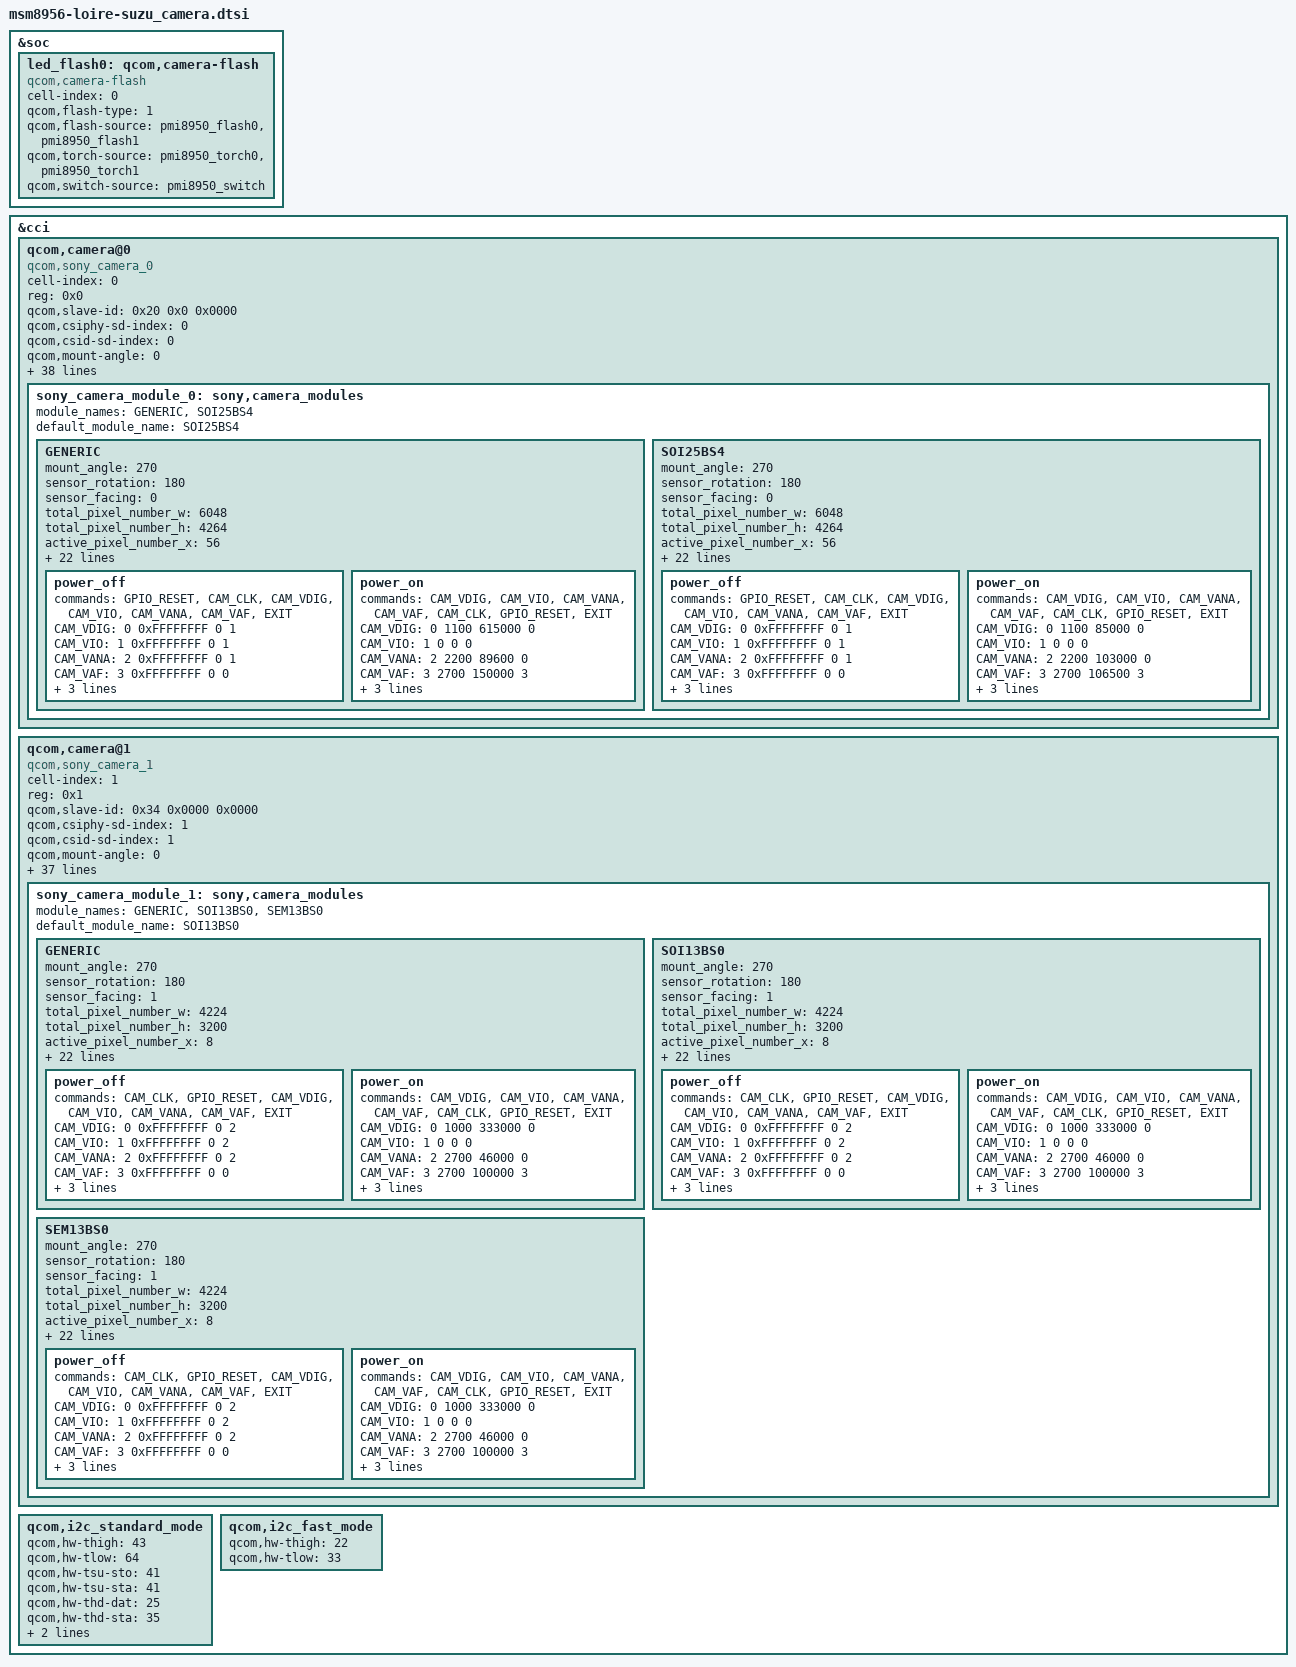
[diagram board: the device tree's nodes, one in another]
/*
 * Copyright (c) 2015-2016, The Linux Foundation. All rights reserved.
 *
 * This program is free software; you can redistribute it and/or modify
 * it under the terms of the GNU General Public License version 2 and
 * only version 2 as published by the Free Software Foundation.
 *
 * This program is distributed in the hope that it will be useful,
 * but WITHOUT ANY WARRANTY; without even the implied warranty of
 * MERCHANTABILITY or FITNESS FOR A PARTICULAR PURPOSE.  See the
 * GNU General Public License for more details.
 */

&soc {
	led_flash0: qcom,camera-flash {
		cell-index = <0>;
		compatible = "qcom,camera-flash";
		qcom,flash-type = <1>;
		qcom,flash-source = <&pmi8950_flash0 &pmi8950_flash1>;
		qcom,torch-source = <&pmi8950_torch0 &pmi8950_torch1>;
		qcom,switch-source = <&pmi8950_switch>;
	};
};

&cci {
	qcom,camera@0 {
		cell-index = <0>;
		compatible = "qcom,sony_camera_0";
		reg = <0x0>;
		status = "ok";
		qcom,slave-id = <0x20 0x0 0x0000>;
		qcom,csiphy-sd-index = <0>;
		qcom,csid-sd-index = <0>;
		qcom,mount-angle = <0>;
		qcom,sensor-name = "sony_camera_0";
		qcom,led-flash-src = <&led_flash0>;
		cam_vdig-supply = <&pm8950_l3>;
		cam_vio-supply = <&pm8950_l5>;
		cam_vana-supply = <&pm8950_l9>;
		cam_vaf-supply = <&pm8950_l17>;
		qcom,cam-vreg-name = "cam_vdig", "cam_vio", "cam_vana", "cam_vaf";
		qcom,cam-vreg-type = <0 1 0 0>;
		qcom,cam-vreg-min-voltage = <1100000 0 2200000 2700000>;
		qcom,cam-vreg-max-voltage = <1100000 0 2200000 2700000>;
		qcom,cam-vreg-op-mode = <615000 0 89600 150000>;
		qcom,gpio-no-mux = <0>;
		pinctrl-names = "cam_default", "cam_suspend";
		pinctrl-0 = <&cam_sensor_mclk0_default &cam_sensor_rear_default>;
		pinctrl-1 = <&cam_sensor_mclk0_sleep &cam_sensor_rear_sleep>;
		gpios = <&msm_gpio 26 0>, <&msm_gpio 35 0>, <&msm_gpio 127 0>;
		qcom,gpio-reset = <1>;
		qcom,gpio-vio = <2>;
		qcom,gpio-req-tbl-num = <0 1 2>;
		qcom,gpio-req-tbl-flags = <1 0 0>;
		qcom,gpio-req-tbl-label = "CAMIF_MCLK0", "CAM_RESET0", "CAM_VIO";
		qcom,csi-lane-assign = <0x4320>;
		qcom,csi-lane-mask = <0x1F>;
		qcom,sensor-position = <0>;
		qcom,sensor-mode = <1>;
		qcom,cci-master = <0>;
		clocks = <&clock_gcc clk_mclk0_clk_src>, <&clock_gcc clk_gcc_camss_mclk0_clk>;
		clock-names = "cam_src_clk", "cam_clk";
		sony,i2c_addr = <0x20>;
		sony,eeprom_addr = <0xA0>;
		sony,eeprom_type = <0>;
		sony,eeprom_max_len = <2048>;
		sony,subdev_code = <0x3007>;
		sony_camera_module_0: sony,camera_modules {
		    status = "disabled";
		};
	};

	qcom,camera@1 {
		cell-index = <1>;
		compatible = "qcom,sony_camera_1";
		reg = <0x1>;
		status = "ok";
		qcom,slave-id = <0x34 0x0000 0x0000>;
		qcom,csiphy-sd-index = <1>;
		qcom,csid-sd-index = <1>;
		qcom,mount-angle = <0>;
		qcom,sensor-name = "sony_camera_1";
		cam_vdig-supply = <&pm8950_l1>;
		cam_vana-supply = <&pm8950_l10>;
		cam_vio-supply = <&pm8950_l5>;
		cam_vaf-supply = <&pm8950_l17>;
		qcom,cam-vreg-name = "cam_vdig", "cam_vana", "cam_vio", "cam_vaf";
		qcom,cam-vreg-type = <0 0 1 0>;
		qcom,cam-vreg-min-voltage = <1000000 2700000 0 2700000>;
		qcom,cam-vreg-max-voltage = <1000000 2700000 0 2700000>;
		qcom,cam-vreg-op-mode = <333000 46000 0 100000>;
		qcom,gpio-no-mux = <0>;
		pinctrl-names = "cam_default", "cam_suspend";
		pinctrl-0 = <&cam_sensor_mclk2_default &cam_sensor_front1_default>;
		pinctrl-1 = <&cam_sensor_mclk2_sleep &cam_sensor_front1_sleep>;
		gpios = <&msm_gpio 28 0>, <&msm_gpio 38 0>, <&msm_gpio 127 0>;
		qcom,gpio-reset = <1>;
		qcom,gpio-vio = <2>;
		qcom,gpio-req-tbl-num = <0 1 2>;
		qcom,gpio-req-tbl-flags = <1 0 0>;
		qcom,gpio-req-tbl-label = "CAMIF_MCLK2", "CAM_RESET2", "CAM_VIO";
		qcom,csi-lane-assign = <0x4320>;
		qcom,csi-lane-mask = <0x1F>;
		qcom,sensor-position = <1>;
		qcom,sensor-mode = <1>;
		qcom,cci-master = <1>;
		clocks = <&clock_gcc clk_mclk2_clk_src>, <&clock_gcc clk_gcc_camss_mclk2_clk>;
		clock-names = "cam_src_clk", "cam_clk";
		sony,i2c_addr = <0x34>;
		sony,eeprom_addr = <0xA0>;
		sony,eeprom_type = <0>;
		sony,eeprom_max_len = <2048>;
		sony,subdev_code = <0x3007>;
		sony_camera_module_1: sony,camera_modules {
		    status = "disabled";
		};
	};

	qcom,i2c_standard_mode {
		qcom,hw-thigh = <43>;
		qcom,hw-tlow = <64>;
		qcom,hw-tsu-sto = <41>;
		qcom,hw-tsu-sta = <41>;
		qcom,hw-thd-dat = <25>;
		qcom,hw-thd-sta = <35>;
		qcom,hw-tbuf = <64>;
		qcom,cci-clk-src = <37500000>;
	};

	qcom,i2c_fast_mode {
		qcom,hw-thigh = <22>;
		qcom,hw-tlow = <33>;
	};
};

&sony_camera_module_0 {
	module_names = "GENERIC", "SOI25BS4";
	default_module_name = "SOI25BS4";
	status = "ok";

	GENERIC {
		mount_angle = <270>;
		sensor_rotation = <180>;
		sensor_facing = <0>;
		total_pixel_number_w = <6048>;
		total_pixel_number_h = <4264>;
		active_pixel_number_x = <56>;
		active_pixel_number_y = <88>;
		active_pixel_number_w = <5984>;
		active_pixel_number_h = <4160>;
		min_focus_distance = <120>;
		hyper_focal_distance = <3679>;
		diagonal_len = "8.17";
		unit_cell_size_w = "1.12";
		unit_cell_size_h = "1.12";
		min_f_number = "2.00";
		max_f_number = "2.00";
		has_3a = <0>;
		has_focus_actuator = <1>;
		need_standby_af = <0>;
		i2c_freq_mode = <3>;
		has_pdaf = <1>;
		has_rs = <1>;
		pdaf_free_area_num = <8>;
		pdaf_fixed_area_size_w = <16>;
		pdaf_fixed_area_size_h = <12>;
		pll_num = <26>;
		pll = <145 109 112 112 122 109 182 75 112 136 145 182 182 145 142 145 104 182 145 145 182 182 182 182 104 112>;
		power_off {
			commands =
				"GPIO_RESET",
				"CAM_CLK",
				"CAM_VDIG",
				"CAM_VIO",
				"CAM_VANA",
				"CAM_VAF",
				"EXIT";
			CAM_VDIG = <0 0xFFFFFFFF 0 1>;
			CAM_VIO = <1 0xFFFFFFFF 0 1>;
			CAM_VANA = <2 0xFFFFFFFF 0 1>;
			CAM_VAF = <3 0xFFFFFFFF 0 0>;
			GPIO_RESET = <8 0x0 0 5>;
			CAM_CLK = <9 0xFFFFFFFF 0 0>;
			EXIT = <11 0x0 0 0>;
		};
		power_on {
			commands =
				"CAM_VDIG",
				"CAM_VIO",
				"CAM_VANA",
				"CAM_VAF",
				"CAM_CLK",
				"GPIO_RESET",
				"EXIT";
			CAM_VDIG = <0 1100 615000 0>;
			CAM_VIO = <1 0 0 0>;
			CAM_VANA = <2 2200 89600 0>;
			CAM_VAF = <3 2700 150000 3>;
			CAM_CLK = <9 0 0 1>;
			GPIO_RESET = <8 1 0 9>;
			EXIT = <11 0x0 0 0>;
		};
	};
	SOI25BS4 {
		mount_angle = <270>;
		sensor_rotation = <180>;
		sensor_facing = <0>;
		total_pixel_number_w = <6048>;
		total_pixel_number_h = <4264>;
		active_pixel_number_x = <56>;
		active_pixel_number_y = <88>;
		active_pixel_number_w = <5984>;
		active_pixel_number_h = <4160>;
		min_focus_distance = <120>;
		hyper_focal_distance = <3679>;
		diagonal_len = "8.17";
		unit_cell_size_w = "1.12";
		unit_cell_size_h = "1.12";
		min_f_number = "2.00";
		max_f_number = "2.00";
		has_3a = <0>;
		has_focus_actuator = <1>;
		need_standby_af = <0>;
		i2c_freq_mode = <3>;
		has_pdaf = <1>;
		has_rs = <1>;
		pdaf_free_area_num = <8>;
		pdaf_fixed_area_size_w = <16>;
		pdaf_fixed_area_size_h = <12>;
		pll_num = <26>;
		pll = <145 109 112 112 122 109 182 75 112 136 145 182 182 145 142 145 104 182 145 145 182 182 182 182 104 112>;
		power_off {
			commands =
				"GPIO_RESET",
				"CAM_CLK",
				"CAM_VDIG",
				"CAM_VIO",
				"CAM_VANA",
				"CAM_VAF",
				"EXIT";
			CAM_VDIG = <0 0xFFFFFFFF 0 1>;
			CAM_VIO = <1 0xFFFFFFFF 0 1>;
			CAM_VANA = <2 0xFFFFFFFF 0 1>;
			CAM_VAF = <3 0xFFFFFFFF 0 0>;
			GPIO_RESET = <8 0x0 0 5>;
			CAM_CLK = <9 0xFFFFFFFF 0 0>;
			EXIT = <11 0x0 0 0>;
		};
		power_on {
			commands =
				"CAM_VDIG",
				"CAM_VIO",
				"CAM_VANA",
				"CAM_VAF",
				"CAM_CLK",
				"GPIO_RESET",
				"EXIT";
			CAM_VDIG = <0 1100 85000 0>;
			CAM_VIO = <1 0 0 0>;
			CAM_VANA = <2 2200 103000 0>;
			CAM_VAF = <3 2700 106500 3>;
			CAM_CLK = <9 0 0 1>;
			GPIO_RESET = <8 1 0 9>;
			EXIT = <11 0x0 0 0>;
		};
	};
};

&sony_camera_module_1 {
	module_names = "GENERIC", "SOI13BS0", "SEM13BS0";
	default_module_name = "SOI13BS0";
	status = "ok";

	GENERIC {
		mount_angle = <270>;
		sensor_rotation = <180>;
		sensor_facing = <1>;
		total_pixel_number_w = <4224>;
		total_pixel_number_h = <3200>;
		active_pixel_number_x = <8>;
		active_pixel_number_y = <72>;
		active_pixel_number_w = <4208>;
		active_pixel_number_h = <3120>;
		min_focus_distance = <100>;
		hyper_focal_distance = <2000>;
		diagonal_len = "5.867";
		unit_cell_size_w = "1.12";
		unit_cell_size_h = "1.12";
		min_f_number = "2.00";
		max_f_number = "2.00";
		has_3a = <0>;
		has_focus_actuator = <1>;
		need_standby_af = <1>;
		i2c_freq_mode = <0>;
		has_pdaf = <0>;
		has_rs = <1>;
		pdaf_free_area_num = <0>;
		pdaf_fixed_area_size_w = <0>;
		pdaf_fixed_area_size_h = <0>;
		pll_num = <26>;
		pll = <1134 1134 1134 1134 1134 1134 1134 1134 1134 1134 1134 1134 1134 1134 1134 1134 1134 1134 1134 1134 1134 1134 1134 1134 1134 1134>;
		power_off {
			commands =
				"CAM_CLK",
				"GPIO_RESET",
				"CAM_VDIG",
				"CAM_VIO",
				"CAM_VANA",
				"CAM_VAF",
				"EXIT";
			CAM_VDIG = <0 0xFFFFFFFF 0 2>;
			CAM_VIO = <1 0xFFFFFFFF 0 2>;
			CAM_VANA = <2 0xFFFFFFFF 0 2>;
			CAM_VAF = <3 0xFFFFFFFF 0 0>;
			GPIO_RESET = <8 0x0 0 5>;
			CAM_CLK = <9 0xFFFFFFFF 0 0>;
			EXIT = <11 0x0 0 0>;
		};
		power_on {
			commands =
				"CAM_VDIG",
				"CAM_VIO",
				"CAM_VANA",
				"CAM_VAF",
				"CAM_CLK",
				"GPIO_RESET",
				"EXIT";
			CAM_VDIG = <0 1000 333000 0>;
			CAM_VIO = <1 0 0 0>;
			CAM_VANA = <2 2700 46000 0>;
			CAM_VAF = <3 2700 100000 3>;
			CAM_CLK = <9 0 0 1>;
			GPIO_RESET = <8 1 0 1>;
			EXIT = <11 0x0 0 0>;
		};
	};
	SOI13BS0 {
		mount_angle = <270>;
		sensor_rotation = <180>;
		sensor_facing = <1>;
		total_pixel_number_w = <4224>;
		total_pixel_number_h = <3200>;
		active_pixel_number_x = <8>;
		active_pixel_number_y = <72>;
		active_pixel_number_w = <4208>;
		active_pixel_number_h = <3120>;
		min_focus_distance = <100>;
		hyper_focal_distance = <2000>;
		diagonal_len = "5.867";
		unit_cell_size_w = "1.12";
		unit_cell_size_h = "1.12";
		min_f_number = "2.00";
		max_f_number = "2.00";
		has_3a = <0>;
		has_focus_actuator = <1>;
		need_standby_af = <1>;
		i2c_freq_mode = <0>;
		has_pdaf = <0>;
		has_rs = <1>;
		pdaf_free_area_num = <0>;
		pdaf_fixed_area_size_w = <0>;
		pdaf_fixed_area_size_h = <0>;
		pll_num = <26>;
		pll = <1134 1134 1134 1134 1134 1134 1134 1134 1134 1134 1134 1134 1134 1134 1134 1134 1134 1134 1134 1134 1134 1134 1134 1134 1134 1134>;
		power_off {
			commands =
				"CAM_CLK",
				"GPIO_RESET",
				"CAM_VDIG",
				"CAM_VIO",
				"CAM_VANA",
				"CAM_VAF",
				"EXIT";
			CAM_VDIG = <0 0xFFFFFFFF 0 2>;
			CAM_VIO = <1 0xFFFFFFFF 0 2>;
			CAM_VANA = <2 0xFFFFFFFF 0 2>;
			CAM_VAF = <3 0xFFFFFFFF 0 0>;
			GPIO_RESET = <8 0x0 0 5>;
			CAM_CLK = <9 0xFFFFFFFF 0 0>;
			EXIT = <11 0x0 0 0>;
		};
		power_on {
			commands =
				"CAM_VDIG",
				"CAM_VIO",
				"CAM_VANA",
				"CAM_VAF",
				"CAM_CLK",
				"GPIO_RESET",
				"EXIT";
			CAM_VDIG = <0 1000 333000 0>;
			CAM_VIO = <1 0 0 0>;
			CAM_VANA = <2 2700 46000 0>;
			CAM_VAF = <3 2700 100000 3>;
			CAM_CLK = <9 0 0 1>;
			GPIO_RESET = <8 1 0 1>;
			EXIT = <11 0x0 0 0>;
		};
	};
	SEM13BS0 {
		mount_angle = <270>;
		sensor_rotation = <180>;
		sensor_facing = <1>;
		total_pixel_number_w = <4224>;
		total_pixel_number_h = <3200>;
		active_pixel_number_x = <8>;
		active_pixel_number_y = <72>;
		active_pixel_number_w = <4208>;
		active_pixel_number_h = <3120>;
		min_focus_distance = <100>;
		hyper_focal_distance = <2000>;
		diagonal_len = "5.867";
		unit_cell_size_w = "1.12";
		unit_cell_size_h = "1.12";
		min_f_number = "2.00";
		max_f_number = "2.00";
		has_3a = <0>;
		has_focus_actuator = <1>;
		need_standby_af = <1>;
		i2c_freq_mode = <0>;
		has_pdaf = <0>;
		has_rs = <1>;
		pdaf_free_area_num = <0>;
		pdaf_fixed_area_size_w = <0>;
		pdaf_fixed_area_size_h = <0>;
		pll_num = <26>;
		pll = <1134 1134 1134 1134 1134 1134 1134 1134 1134 1134 1134 1134 1134 1134 1134 1134 1134 1134 1134 1134 1134 1134 1134 1134 1134 1134>;
		power_off {
			commands =
				"CAM_CLK",
				"GPIO_RESET",
				"CAM_VDIG",
				"CAM_VIO",
				"CAM_VANA",
				"CAM_VAF",
				"EXIT";
			CAM_VDIG = <0 0xFFFFFFFF 0 2>;
			CAM_VIO = <1 0xFFFFFFFF 0 2>;
			CAM_VANA = <2 0xFFFFFFFF 0 2>;
			CAM_VAF = <3 0xFFFFFFFF 0 0>;
			GPIO_RESET = <8 0x0 0 5>;
			CAM_CLK = <9 0xFFFFFFFF 0 0>;
			EXIT = <11 0x0 0 0>;
		};
		power_on {
			commands =
				"CAM_VDIG",
				"CAM_VIO",
				"CAM_VANA",
				"CAM_VAF",
				"CAM_CLK",
				"GPIO_RESET",
				"EXIT";
			CAM_VDIG = <0 1000 333000 0>;
			CAM_VIO = <1 0 0 0>;
			CAM_VANA = <2 2700 46000 0>;
			CAM_VAF = <3 2700 100000 3>;
			CAM_CLK = <9 0 0 1>;
			GPIO_RESET = <8 1 0 1>;
			EXIT = <11 0x0 0 0>;
		};
	};
};
